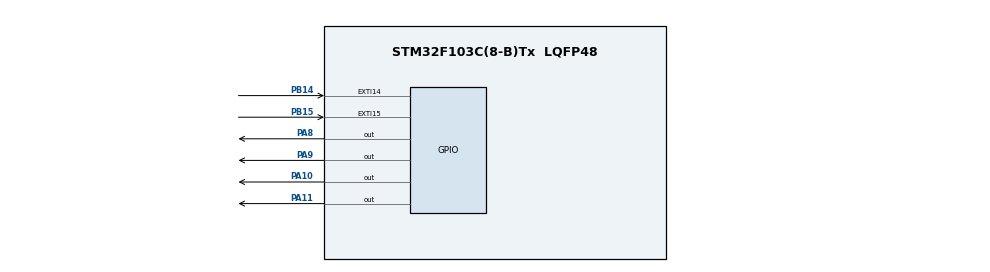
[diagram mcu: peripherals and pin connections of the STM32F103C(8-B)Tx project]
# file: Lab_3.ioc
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Mcu.Family=STM32F1
Mcu.Name=STM32F103C(8-B)Tx
Mcu.Package=LQFP48
NVIC.EXTI15_10_IRQn=true\:0\:0\:false\:true\:true\:1\:true\:true
NVIC.PriorityGroup=NVIC_PRIORITYGROUP_4
PA10.Signal=GPIO_Output
PA11.Signal=GPIO_Output
PA8.Signal=GPIO_Output
PA9.Signal=GPIO_Output
PB14.Signal=GPXTI14
PB15.Signal=GPXTI15
ProjectManager.HeapSize=0x200
ProjectManager.StackSize=0x400
ProjectManager.TargetToolchain=STM32CubeIDE
RCC.APB1Freq_Value=8000000
RCC.APB2Freq_Value=8000000
VP_SYS_VS_ND.Mode=No_Debug
board=custom

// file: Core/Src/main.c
/* USER CODE BEGIN Header */
/**
  ******************************************************************************
  * @file           : main.c
  * @brief          : Main program body
  ******************************************************************************
  * @attention
  *
  * <h2><center>&copy; Copyright (c) 2021 STMicroelectronics.
  * All rights reserved.</center></h2>
  *
  * This software component is licensed by ST under BSD 3-Clause license,
  * the "License"; You may not use this file except in compliance with the
  * License. You may obtain a copy of the License at:
  *                        opensource.org/licenses/BSD-3-Clause
  *
  ******************************************************************************
  */
/* USER CODE END Header */
#include "main.h"
#include "gpio.h"

/* USER CODE BEGIN PV */
const char *Pins[] = {GPIO_PIN_8,GPIO_PIN_9,GPIO_PIN_10,GPIO_PIN_11};//Массив пинов светодиодов
int status[4] = {0,0,0,0};//Массив статуса светодиодов
int incr = 0;//Флаг инкремента
int decr = 0;//Флаг декремента
int counter = 0;//Счетчик включенных светодиодов
/* USER CODE END PV */

void SystemClock_Config(void);
static void MX_NVIC_Init(void);

int main(void)
{

  /* MCU Configuration--------------------------------------------------------*/

  /* Reset of all peripherals, Initializes the Flash interface and the Systick. */
  HAL_Init();

  /* Configure the system clock */
  SystemClock_Config();

  /* Initialize all configured peripherals */
  MX_GPIO_Init();

  /* Initialize interrupts */
  MX_NVIC_Init();

  /* Infinite loop */
  while (1)
  {
  	  //Цикл зажигания светодиодов
  	  for(int i = 0; i < sizeof(Pins)/ sizeof(Pins[0]);i++)
  	  {

  		  HAL_GPIO_WritePin(GPIOA, Pins[i], status[i]);
  	  }

  	  //Включение первого светодиода
	  if(counter == 0 && incr == 1){
		  HAL_Delay(200);//Задержка для избежания дребезга контактов
		  status[0] = 1;
		  incr = 0;
		  counter++;
	  }
	  //Включение одного светодиода
	  if(incr == 1){
		  HAL_Delay(200);//Задержка для избежания дребезга контактов
		  for(int i = 0;i < sizeof(status)/ sizeof(status[0]);i++){
			  if(status[i] == 0 && counter < sizeof(status)/ sizeof(status[0])){
				  status[i] = 1;
				  incr = 0;
				  counter++;
				  break;
			  }
		  }
	  }
	  //Выключение одного светодиода
	  if(decr == 1){
		   HAL_Delay(200);//Задержка для избежания дребезга контактов
		   for(int i = sizeof(status)/ sizeof(status[0]);i >= 0;i--){
			   if(status[i] == 1 && counter > 0){
				  status[i] = 0;
				  decr = 0;
				  counter--;
				  break;
			  }
		  }
	  }

  }
}

void SystemClock_Config(void)
{
  RCC_OscInitTypeDef RCC_OscInitStruct = {0};
  RCC_ClkInitTypeDef RCC_ClkInitStruct = {0};

  /** Initializes the RCC Oscillators according to the specified parameters
  * in the RCC_OscInitTypeDef structure.
  */
  RCC_OscInitStruct.OscillatorType = RCC_OSCILLATORTYPE_HSI;
  RCC_OscInitStruct.HSIState = RCC_HSI_ON;
  RCC_OscInitStruct.HSICalibrationValue = RCC_HSICALIBRATION_DEFAULT;
  RCC_OscInitStruct.PLL.PLLState = RCC_PLL_NONE;
  if (HAL_RCC_OscConfig(&RCC_OscInitStruct) != HAL_OK)
  {
    Error_Handler();
  }
  /** Initializes the CPU, AHB and APB buses clocks
  */
  RCC_ClkInitStruct.ClockType = RCC_CLOCKTYPE_HCLK|RCC_CLOCKTYPE_SYSCLK
                              |RCC_CLOCKTYPE_PCLK1|RCC_CLOCKTYPE_PCLK2;
  RCC_ClkInitStruct.SYSCLKSource = RCC_SYSCLKSOURCE_HSI;
  RCC_ClkInitStruct.AHBCLKDivider = RCC_SYSCLK_DIV1;
  RCC_ClkInitStruct.APB1CLKDivider = RCC_HCLK_DIV1;
  RCC_ClkInitStruct.APB2CLKDivider = RCC_HCLK_DIV1;

  if (HAL_RCC_ClockConfig(&RCC_ClkInitStruct, FLASH_LATENCY_0) != HAL_OK)
  {
    Error_Handler();
  }
}

/**
  * @brief NVIC Configuration.
  * @retval None
  */
static void MX_NVIC_Init(void)
{
  /* EXTI15_10_IRQn interrupt configuration */
  HAL_NVIC_SetPriority(EXTI15_10_IRQn, 0, 0);
  HAL_NVIC_EnableIRQ(EXTI15_10_IRQn);
}

/* USER CODE BEGIN 4 */
void HAL_GPIO_EXTI_Callback(uint16_t GPIO_Pin)
{
	if(GPIO_Pin == GPIO_PIN_14){
		decr = 1;
	}
	if(GPIO_Pin == GPIO_PIN_15){
		incr = 1;
	}
}
/* USER CODE END 4 */

void Error_Handler(void)
{
  __disable_irq();
  while (1)
  {
  }
}

/************************ (C) COPYRIGHT STMicroelectronics *****END OF FILE****/
